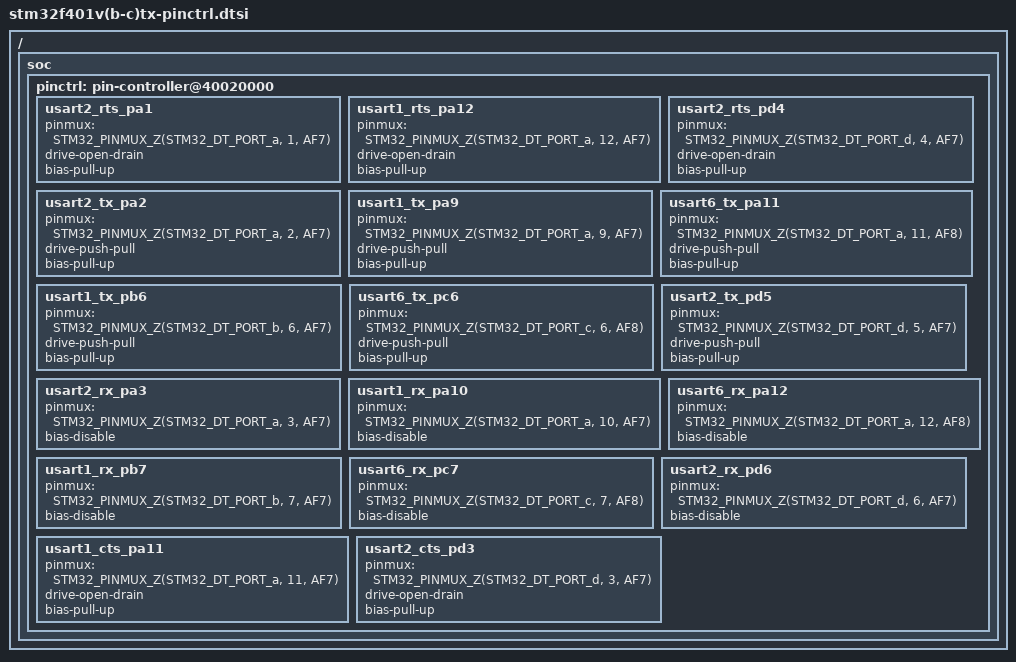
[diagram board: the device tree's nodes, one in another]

/*
 * NOTE: Autogenerated file using stm32_pinctrl_gen.py
 *
 * SPDX-License-Identifier: Apache-2.0
 */

#include <dt-bindings/pinctrl/stm32-pinctrl.h>

/ {
	soc {
		pinctrl: pin-controller@40020000 {
			/* UART_RTS */
			usart2_rts_pa1: usart2_rts_pa1 {
				pinmux = <STM32_PINMUX_Z(STM32_DT_PORT_a, 1, AF7)>;
				drive-open-drain;
				bias-pull-up;
			};

			usart1_rts_pa12: usart1_rts_pa12 {
				pinmux = <STM32_PINMUX_Z(STM32_DT_PORT_a, 12, AF7)>;
				drive-open-drain;
				bias-pull-up;
			};

			usart2_rts_pd4: usart2_rts_pd4 {
				pinmux = <STM32_PINMUX_Z(STM32_DT_PORT_d, 4, AF7)>;
				drive-open-drain;
				bias-pull-up;
			};


			/* UART_TX */
			usart2_tx_pa2: usart2_tx_pa2 {
				pinmux = <STM32_PINMUX_Z(STM32_DT_PORT_a, 2, AF7)>;
				drive-push-pull;
				bias-pull-up;
			};

			usart1_tx_pa9: usart1_tx_pa9 {
				pinmux = <STM32_PINMUX_Z(STM32_DT_PORT_a, 9, AF7)>;
				drive-push-pull;
				bias-pull-up;
			};

			usart6_tx_pa11: usart6_tx_pa11 {
				pinmux = <STM32_PINMUX_Z(STM32_DT_PORT_a, 11, AF8)>;
				drive-push-pull;
				bias-pull-up;
			};

			usart1_tx_pb6: usart1_tx_pb6 {
				pinmux = <STM32_PINMUX_Z(STM32_DT_PORT_b, 6, AF7)>;
				drive-push-pull;
				bias-pull-up;
			};

			usart6_tx_pc6: usart6_tx_pc6 {
				pinmux = <STM32_PINMUX_Z(STM32_DT_PORT_c, 6, AF8)>;
				drive-push-pull;
				bias-pull-up;
			};

			usart2_tx_pd5: usart2_tx_pd5 {
				pinmux = <STM32_PINMUX_Z(STM32_DT_PORT_d, 5, AF7)>;
				drive-push-pull;
				bias-pull-up;
			};


			/* UART_RX */
			usart2_rx_pa3: usart2_rx_pa3 {
				pinmux = <STM32_PINMUX_Z(STM32_DT_PORT_a, 3, AF7)>;
				bias-disable;
			};

			usart1_rx_pa10: usart1_rx_pa10 {
				pinmux = <STM32_PINMUX_Z(STM32_DT_PORT_a, 10, AF7)>;
				bias-disable;
			};

			usart6_rx_pa12: usart6_rx_pa12 {
				pinmux = <STM32_PINMUX_Z(STM32_DT_PORT_a, 12, AF8)>;
				bias-disable;
			};

			usart1_rx_pb7: usart1_rx_pb7 {
				pinmux = <STM32_PINMUX_Z(STM32_DT_PORT_b, 7, AF7)>;
				bias-disable;
			};

			usart6_rx_pc7: usart6_rx_pc7 {
				pinmux = <STM32_PINMUX_Z(STM32_DT_PORT_c, 7, AF8)>;
				bias-disable;
			};

			usart2_rx_pd6: usart2_rx_pd6 {
				pinmux = <STM32_PINMUX_Z(STM32_DT_PORT_d, 6, AF7)>;
				bias-disable;
			};


			/* UART_CTS */
			usart1_cts_pa11: usart1_cts_pa11 {
				pinmux = <STM32_PINMUX_Z(STM32_DT_PORT_a, 11, AF7)>;
				drive-open-drain;
				bias-pull-up;
			};

			usart2_cts_pd3: usart2_cts_pd3 {
				pinmux = <STM32_PINMUX_Z(STM32_DT_PORT_d, 3, AF7)>;
				drive-open-drain;
				bias-pull-up;
			};

		};
	};
};
